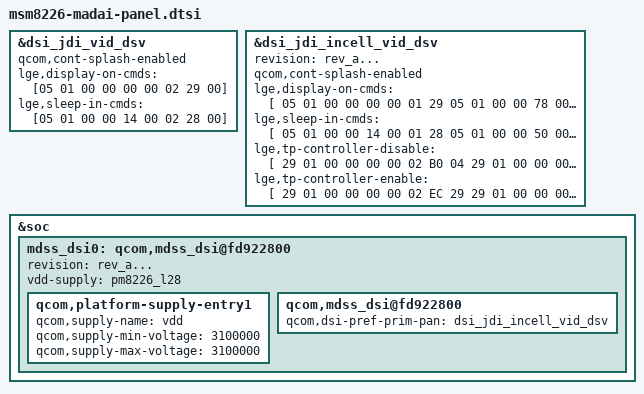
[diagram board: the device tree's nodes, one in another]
/* Copyright (c) 2013, Code Aurora Forum. All rights reserved.
 *
 * This program is free software; you can redistribute it and/or modify
 * it under the terms of the GNU General Public License version 2 and
 * only version 2 as published by the Free Software Foundation.
 *
 * This program is distributed in the hope that it will be useful,
 * but WITHOUT ANY WARRANTY; without even the implied warranty of
 * MERCHANTABILITY or FITNESS FOR A PARTICULAR PURPOSE.  See the
 * GNU General Public License for more details.
 */

&mdss_dsi0 {
	qcom,mdss_dsi@fd922800 {
		qcom,dsi-pref-prim-pan = <&dsi_jdi_incell_vid_dsv>;
	};
};

&dsi_jdi_vid_dsv{
	status = "ok";
	qcom,cont-splash-enabled;
	lge,display-on-cmds = [05 01 00 00 00 00 02
		29 00];
	lge,sleep-in-cmds = [05 01 00 00 14 00 02
		28 00];
};

&dsi_jdi_incell_vid_dsv{
	status = "ok";
	revision = "rev_a...";
	qcom,cont-splash-enabled;
	/*qcom,mdss-dsi-panel-clockrate = <430960000>;*/
	lge,display-on-cmds = [
		05 01 00 00 00 00 01 /* display on */
		29
		05 01 00 00 78 00 01 /* exit sleep - wait 120ms */
		11
	];
	lge,sleep-in-cmds = [
		05 01 00 00 14 00 01 /* display off - wait 20ms*/
		28
		05 01 00 00 50 00 01 /* enter sleep - wait 80ms */
		10
	];
	lge,tp-controller-disable = [
		29 01 00 00 00 00 02
		B0 04
		29 01 00 00 00 00 02
		EC 09
	];
	lge,tp-controller-enable = [
		29 01 00 00 00 00 02
		EC 29
		29 01 00 00 00 00 02
		B0 03
	];
};

&soc {
	mdss_dsi0: qcom,mdss_dsi@fd922800 {
		status = "ok";
		revision = "rev_a...";
		vdd-supply = <&pm8226_l28>;
		qcom,platform-supply-entry1 {
			qcom,supply-name = "vdd";
			qcom,supply-min-voltage = <3100000>;
			qcom,supply-max-voltage = <3100000>;
		};
	};
};
